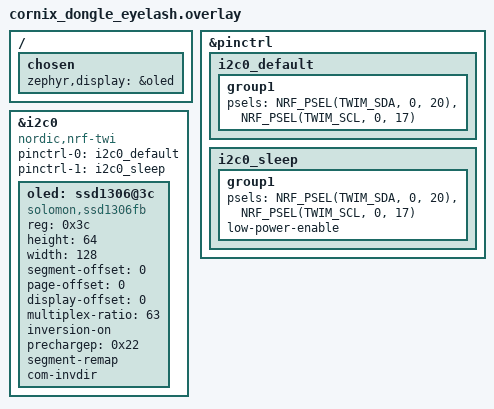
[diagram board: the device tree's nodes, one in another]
#include <dt-bindings/zmk/matrix_transform.h>

/{
    chosen {
        zephyr,display = &oled;
    };
};
// vim: set ft=dts :
&pinctrl {
    i2c0_default: i2c0_default {
        group1 {
            psels = <NRF_PSEL(TWIM_SDA, 0, 20)>,
                <NRF_PSEL(TWIM_SCL, 0, 17)>;
        };
    };

    i2c0_sleep: i2c0_sleep {
        group1 {
            psels = <NRF_PSEL(TWIM_SDA, 0, 20)>,
                <NRF_PSEL(TWIM_SCL, 0, 17)>;
            low-power-enable;
        };
    };
};


&i2c0 {
	status = "okay";
	compatible = "nordic,nrf-twi";
    pinctrl-0 = <&i2c0_default>;
    pinctrl-1 = <&i2c0_sleep>;
	oled: ssd1306@3c {
        /*
         * SSD1315 / SSD1306-class OLED on I2C.
         * Zephyr 3.5 + ZMK v0.3 use compatible solomon,ssd1306fb (not solomon,ssd1306)
         * or LVGL fails: DT_PROP(..., width) missing on chosen display.
         */
        compatible = "solomon,ssd1306fb";
        reg = <0x3c>;
        height = <64>;

        width = <128>;
        segment-offset = <0>;

        page-offset = <0>;
        display-offset = <0>;
        multiplex-ratio = <63>;
        inversion-on;
        prechargep = <0x22>;

        // comment to rotate 180
        segment-remap;
        com-invdir;
	};
};

//vim: set ft=dts:
